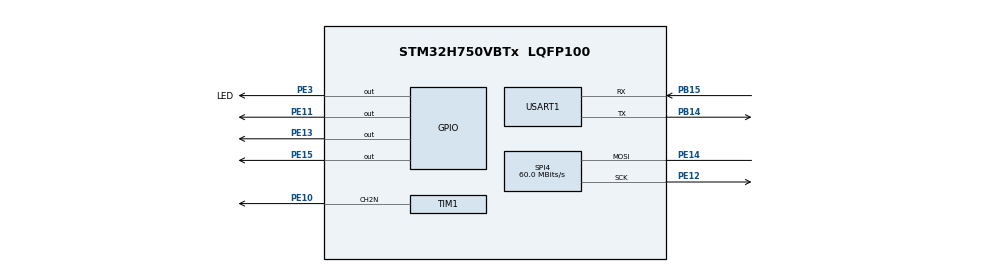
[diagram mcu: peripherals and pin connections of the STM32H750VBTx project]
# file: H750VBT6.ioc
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CORTEX_M7.CPU_ICache=Enabled
CORTEX_M7.default_mode_Activation=1
Mcu.Family=STM32H7
Mcu.Name=STM32H750VBTx
Mcu.Package=LQFP100
NVIC.PriorityGroup=NVIC_PRIORITYGROUP_4
PA13\ (JTMS/SWDIO).Mode=Serial_Wire
PA13\ (JTMS/SWDIO).Signal=DEBUG_JTMS-SWDIO
PA14\ (JTCK/SWCLK).Mode=Serial_Wire
PA14\ (JTCK/SWCLK).Signal=DEBUG_JTCK-SWCLK
PB14.Mode=Asynchronous
PB14.Signal=USART1_TX
PB15.Mode=Asynchronous
PB15.Signal=USART1_RX
PE10.Mode=Output Compare2 CH2N
PE10.Signal=TIM1_CH2N
PE11.Signal=GPIO_Output
PE12.Mode=Simplex_Bidirectional_Master
PE12.Signal=SPI4_SCK
PE13.Signal=GPIO_Output
PE14.Mode=Simplex_Bidirectional_Master
PE14.Signal=SPI4_MOSI
PE15.GPIO_Speed=GPIO_SPEED_FREQ_LOW
PE15.Signal=GPIO_Output
PE3.GPIO_Label=LED
PE3.Signal=GPIO_Output
PH0-OSC_IN\ (PH0).Mode=HSE-External-Oscillator
PH0-OSC_IN\ (PH0).Signal=RCC_OSC_IN
PH1-OSC_OUT\ (PH1).Mode=HSE-External-Oscillator
PH1-OSC_OUT\ (PH1).Signal=RCC_OSC_OUT
ProjectManager.HeapSize=0x200
ProjectManager.StackSize=0x400
ProjectManager.TargetToolchain=CMake
RCC.ADCFreq_Value=129000000
RCC.APB1Freq_Value=120000000
RCC.APB2Freq_Value=120000000
RCC.APB3Freq_Value=120000000
RCC.APB4Freq_Value=120000000
RCC.CortexFreq_Value=480000000
RCC.D1PPRE=RCC_APB3_DIV2
RCC.D2PPRE1=RCC_APB1_DIV2
RCC.D2PPRE2=RCC_APB2_DIV2
RCC.D3PPRE=RCC_APB4_DIV2
RCC.DIVM1=4
RCC.DIVN1=60
RCC.DIVQ1=5
RCC.HCLKFreq_Value=240000000
RCC.HPRE=RCC_HCLK_DIV2
RCC.PLL2FRACN=0
RCC.PLL3FRACN=0
RCC.PLLFRACN=0
RCC.SYSCLKFreq_VALUE=480000000
RCC.SYSCLKSource=RCC_SYSCLKSOURCE_PLLCLK
RCC.USBFreq_Value=192000000
SPI4.CalculateBaudRate=60.0 MBits/s
SPI4.Direction=SPI_DIRECTION_1LINE
SPI4.Mode=SPI_MODE_MASTER
SPI4.VirtualType=VM_MASTER
TIM1.Channel-Output\ Compare2\ CH2N=TIM_CHANNEL_2
TIM1.Period=1000 -1
TIM1.Prescaler=240 - 1
USART1.VirtualMode-Asynchronous=VM_ASYNC
VP_MEMORYMAP_VS_MEMORYMAP.Mode=CurAppReg
board=custom

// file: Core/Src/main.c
/* USER CODE BEGIN Header */
/**
 ******************************************************************************
 * @file           : main.c
 * @brief          : Main program body
 ******************************************************************************
 * @attention
 *
 * Copyright (c) 2025 STMicroelectronics.
 * All rights reserved.
 *
 * This software is licensed under terms that can be found in the LICENSE file
 * in the root directory of this software component.
 * If no LICENSE file comes with this software, it is provided AS-IS.
 *
 ******************************************************************************
 */
/* USER CODE END Header */
#include "main.h"
#include "memorymap.h"
#include "spi.h"
#include "tim.h"
#include "usart.h"
#include "gpio.h"

void SystemClock_Config(void);
static void MPU_Config(void);

/* USER CODE BEGIN 0 */

// printf重定向
#ifdef __GNUC__
#define PUTCHAR_PROTOTYPE int __io_putchar(int ch)
#else
#define PUTCHAR_PROTOTYPE int fputc(int ch, FILE *f)
#endif

PUTCHAR_PROTOTYPE
{
  HAL_UART_Transmit(&huart1, (uint8_t *)&ch, 1, HAL_MAX_DELAY);
  return ch;
}

/* USER CODE END 0 */

int main(void)
{

  /* MPU Configuration--------------------------------------------------------*/
  MPU_Config();

  /* Enable the CPU Cache */

  /* Enable I-Cache---------------------------------------------------------*/
  SCB_EnableICache();

  /* MCU Configuration--------------------------------------------------------*/

  /* Reset of all peripherals, Initializes the Flash interface and the Systick. */
  HAL_Init();

  /* Configure the system clock */
  SystemClock_Config();

  /* Initialize all configured peripherals */
  MX_GPIO_Init();
  MX_SPI4_Init();
  MX_TIM1_Init();
  MX_USART1_UART_Init();

  /* Infinite loop */
  while (1)
  {

  }
}

void SystemClock_Config(void)
{
  RCC_OscInitTypeDef RCC_OscInitStruct = {0};
  RCC_ClkInitTypeDef RCC_ClkInitStruct = {0};

  /** Supply configuration update enable
   */
  HAL_PWREx_ConfigSupply(PWR_LDO_SUPPLY);

  /** Configure the main internal regulator output voltage
   */
  __HAL_PWR_VOLTAGESCALING_CONFIG(PWR_REGULATOR_VOLTAGE_SCALE0);

  while (!__HAL_PWR_GET_FLAG(PWR_FLAG_VOSRDY))
  {
  }

  /** Initializes the RCC Oscillators according to the specified parameters
   * in the RCC_OscInitTypeDef structure.
   */
  RCC_OscInitStruct.OscillatorType = RCC_OSCILLATORTYPE_HSI;
  RCC_OscInitStruct.HSIState = RCC_HSI_DIV1;
  RCC_OscInitStruct.HSICalibrationValue = RCC_HSICALIBRATION_DEFAULT;
  RCC_OscInitStruct.PLL.PLLState = RCC_PLL_ON;
  RCC_OscInitStruct.PLL.PLLSource = RCC_PLLSOURCE_HSI;
  RCC_OscInitStruct.PLL.PLLM = 4;
  RCC_OscInitStruct.PLL.PLLN = 60;
  RCC_OscInitStruct.PLL.PLLP = 2;
  RCC_OscInitStruct.PLL.PLLQ = 5;
  RCC_OscInitStruct.PLL.PLLR = 2;
  RCC_OscInitStruct.PLL.PLLRGE = RCC_PLL1VCIRANGE_3;
  RCC_OscInitStruct.PLL.PLLVCOSEL = RCC_PLL1VCOWIDE;
  RCC_OscInitStruct.PLL.PLLFRACN = 0;
  if (HAL_RCC_OscConfig(&RCC_OscInitStruct) != HAL_OK)
  {
    Error_Handler();
  }

  /** Initializes the CPU, AHB and APB buses clocks
   */
  RCC_ClkInitStruct.ClockType = RCC_CLOCKTYPE_HCLK | RCC_CLOCKTYPE_SYSCLK | RCC_CLOCKTYPE_PCLK1 | RCC_CLOCKTYPE_PCLK2 | RCC_CLOCKTYPE_D3PCLK1 | RCC_CLOCKTYPE_D1PCLK1;
  RCC_ClkInitStruct.SYSCLKSource = RCC_SYSCLKSOURCE_PLLCLK;
  RCC_ClkInitStruct.SYSCLKDivider = RCC_SYSCLK_DIV1;
  RCC_ClkInitStruct.AHBCLKDivider = RCC_HCLK_DIV2;
  RCC_ClkInitStruct.APB3CLKDivider = RCC_APB3_DIV2;
  RCC_ClkInitStruct.APB1CLKDivider = RCC_APB1_DIV2;
  RCC_ClkInitStruct.APB2CLKDivider = RCC_APB2_DIV2;
  RCC_ClkInitStruct.APB4CLKDivider = RCC_APB4_DIV2;

  if (HAL_RCC_ClockConfig(&RCC_ClkInitStruct, FLASH_LATENCY_4) != HAL_OK)
  {
    Error_Handler();
  }
}

/* MPU Configuration */

void MPU_Config(void)
{
  MPU_Region_InitTypeDef MPU_InitStruct = {0};

  /* Disables the MPU */
  HAL_MPU_Disable();

  /** Initializes and configures the Region and the memory to be protected
   */
  MPU_InitStruct.Enable = MPU_REGION_ENABLE;
  MPU_InitStruct.Number = MPU_REGION_NUMBER0;
  MPU_InitStruct.BaseAddress = 0x0;
  MPU_InitStruct.Size = MPU_REGION_SIZE_4GB;
  MPU_InitStruct.SubRegionDisable = 0x87;
  MPU_InitStruct.TypeExtField = MPU_TEX_LEVEL0;
  MPU_InitStruct.AccessPermission = MPU_REGION_NO_ACCESS;
  MPU_InitStruct.DisableExec = MPU_INSTRUCTION_ACCESS_DISABLE;
  MPU_InitStruct.IsShareable = MPU_ACCESS_SHAREABLE;
  MPU_InitStruct.IsCacheable = MPU_ACCESS_NOT_CACHEABLE;
  MPU_InitStruct.IsBufferable = MPU_ACCESS_NOT_BUFFERABLE;

  HAL_MPU_ConfigRegion(&MPU_InitStruct);
  /* Enables the MPU */
  HAL_MPU_Enable(MPU_PRIVILEGED_DEFAULT);
}

void Error_Handler(void)
{
  __disable_irq();
  while (1)
  {
  }
}
